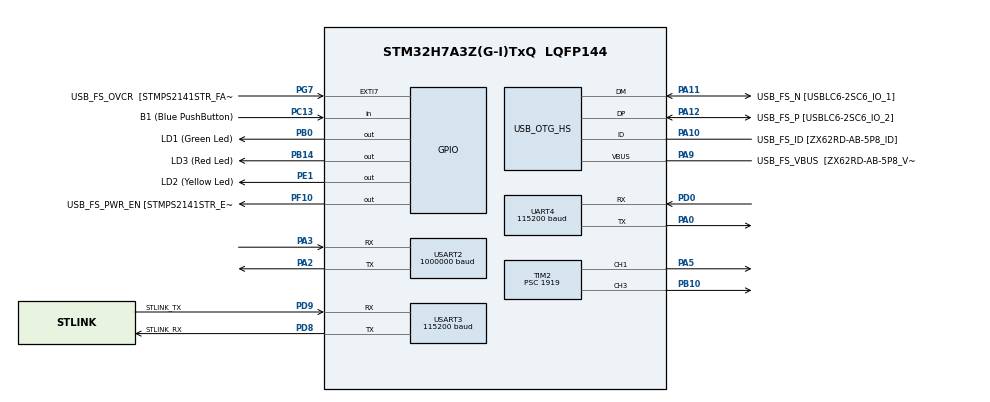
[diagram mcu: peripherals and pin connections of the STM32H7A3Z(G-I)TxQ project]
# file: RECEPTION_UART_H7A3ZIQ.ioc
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Dma.Request0=USART2_RX
Dma.USART2_RX.0.Direction=DMA_PERIPH_TO_MEMORY
Dma.USART2_RX.0.EventEnable=DISABLE
Dma.USART2_RX.0.FIFOMode=DMA_FIFOMODE_DISABLE
Dma.USART2_RX.0.Instance=DMA1_Stream0
Dma.USART2_RX.0.MemDataAlignment=DMA_MDATAALIGN_BYTE
Dma.USART2_RX.0.MemInc=DMA_MINC_ENABLE
Dma.USART2_RX.0.Mode=DMA_NORMAL
Dma.USART2_RX.0.PeriphDataAlignment=DMA_PDATAALIGN_BYTE
Dma.USART2_RX.0.PeriphInc=DMA_PINC_DISABLE
Dma.USART2_RX.0.Polarity=HAL_DMAMUX_REQ_GEN_RISING
Dma.USART2_RX.0.Priority=DMA_PRIORITY_LOW
Dma.USART2_RX.0.RequestNumber=1
Dma.USART2_RX.0.SignalID=NONE
Dma.USART2_RX.0.SyncEnable=DISABLE
Dma.USART2_RX.0.SyncPolarity=HAL_DMAMUX_SYNC_NO_EVENT
Dma.USART2_RX.0.SyncRequestNumber=1
Dma.USART2_RX.0.SyncSignalID=NONE
Mcu.Family=STM32H7
Mcu.Name=STM32H7A3Z(G-I)TxQ
Mcu.Package=LQFP144
NVIC.DMA1_Stream0_IRQn=true\:0\:0\:false\:false\:true\:false\:true\:true
NVIC.PriorityGroup=NVIC_PRIORITYGROUP_4
NVIC.TIM3_IRQn=true\:0\:0\:false\:false\:true\:true\:true\:true
NVIC.UART4_IRQn=true\:0\:0\:false\:false\:true\:true\:true\:true
PA0.Mode=Asynchronous
PA0.Signal=UART4_TX
PA10.GPIO_Label=USB_FS_ID [ZX62RD-AB-5P8_ID]
PA10.Mode=OTG/Dual-Role-Device-FS
PA10.Signal=USB_OTG_HS_ID
PA11.GPIO_Label=USB_FS_N [USBLC6-2SC6_IO_1]
PA11.Mode=OTG/Dual-Role-Device-FS
PA11.Signal=USB_OTG_HS_DM
PA12.GPIO_Label=USB_FS_P [USBLC6-2SC6_IO_2]
PA12.Mode=OTG/Dual-Role-Device-FS
PA12.Signal=USB_OTG_HS_DP
PA2.GPIO_PuPd=GPIO_PULLUP
PA2.Mode=Asynchronous
PA2.Signal=USART2_TX
PA3.Mode=Asynchronous
PA3.Signal=USART2_RX
PA5.Signal=S_TIM2_CH1_ETR
PA9.GPIO_Label=USB_FS_VBUS  [ZX62RD-AB-5P8_VBUS]
PA9.Mode=Activate_VBUS_FS
PA9.Signal=USB_OTG_HS_VBUS
PB0.GPIO_Label=LD1 (Green Led)
PB0.Signal=GPIO_Output
PB10.Signal=S_TIM2_CH3
PB14.GPIO_Label=LD3 (Red Led)
PB14.Signal=GPIO_Output
PC13.GPIO_Label=B1 (Blue PushButton)
PC13.Signal=GPIO_Input
PC14-OSC32_IN.GPIO_Label=OSC32_IN
PC14-OSC32_IN.Mode=LSE-External-Oscillator
PC14-OSC32_IN.Signal=RCC_OSC32_IN
PC15-OSC32_OUT.GPIO_Label=OSC32_OUT
PC15-OSC32_OUT.Mode=LSE-External-Oscillator
PC15-OSC32_OUT.Signal=RCC_OSC32_OUT
PD0.Mode=Asynchronous
PD0.Signal=UART4_RX
PD8.GPIO_Label=STLINK_RX
PD8.Mode=Asynchronous
PD8.Signal=USART3_TX
PD9.GPIO_Label=STLINK_TX
PD9.Mode=Asynchronous
PD9.Signal=USART3_RX
PE1.GPIO_Label=LD2 (Yellow Led)
PE1.Signal=GPIO_Output
PF10.GPIO_Label=USB_FS_PWR_EN [STMPS2141STR_EN]
PF10.Signal=GPIO_Output
PG7.GPIO_Label=USB_FS_OVCR  [STMPS2141STR_FAULT]
PG7.Signal=GPXTI7
PH0-OSC_IN.GPIO_Label=PH0-MCU
PH0-OSC_IN.Mode=HSE-External-Clock-Source
PH0-OSC_IN.Signal=RCC_OSC_IN
PH1-OSC_OUT.GPIO_Label=PH1-MCU
PH1-OSC_OUT.Signal=RCC_OSC_OUT
ProjectManager.HeapSize=0x200
ProjectManager.StackSize=0x400
ProjectManager.TargetToolchain=STM32CubeIDE
RCC.ADCFreq_Value=16125000
RCC.APB1Freq_Value=96000000
RCC.APB2Freq_Value=96000000
RCC.APB3Freq_Value=96000000
RCC.APB4Freq_Value=96000000
RCC.CortexFreq_Value=96000000
RCC.DIVM1=1
RCC.DIVM3=1
RCC.DIVN1=24
RCC.DIVN3=24
RCC.DIVQ1=4
RCC.HCLKFreq_Value=96000000
RCC.HSE_VALUE=8000000
RCC.PLLFRACN=0
RCC.PLLSourceVirtual=RCC_PLLSOURCE_HSE
RCC.PWR_Regulator_Voltage_Scale=PWR_REGULATOR_VOLTAGE_SCALE0
RCC.SYSCLKFreq_VALUE=96000000
RCC.SYSCLKSource=RCC_SYSCLKSOURCE_PLLCLK
RCC.SupplySource=PWR_DIRECT_SMPS_SUPPLY
RCC.USBCLockSelection=RCC_USBCLKSOURCE_HSI48
RCC.USBFreq_Value=48000000
SH.S_TIM2_CH1_ETR.0=TIM2_CH1,PWM Generation1 CH1
SH.S_TIM2_CH3.0=TIM2_CH3,PWM Generation3 CH3
TIM2.Channel-PWM\ Generation1\ CH1=TIM_CHANNEL_1
TIM2.Channel-PWM\ Generation3\ CH3=TIM_CHANNEL_3
TIM2.OCPolarity_3=TIM_OCPOLARITY_HIGH
TIM2.Period=999
TIM2.Prescaler=1919
TIM2.Pulse-PWM\ Generation1\ CH1=0
TIM3.ClockDivision=TIM_CLOCKDIVISION_DIV2
TIM3.Period=39999
TIM3.Prescaler=9599
UART4.BaudRate=115200
USART2.BaudRate=1000000
USART2.TxPinLevelInvertParam=ADVFEATURE_TXINV_DISABLE
USART2.VirtualMode-Asynchronous=VM_ASYNC
USART3.BaudRate=115200
USART3.VirtualMode-Asynchronous=VM_ASYNC
VP_TIM2_VS_ClockSourceINT.Mode=Internal
VP_TIM3_VS_ClockSourceINT.Mode=Internal
board=NUCLEO-H7A3ZI-Q

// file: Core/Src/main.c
/* USER CODE BEGIN Header */
/**
 ******************************************************************************
 * @file           : main.c
 * @brief          : Main program body
 ******************************************************************************
 * @attention
 *
 * Copyright (c) 2023 STMicroelectronics.
 * All rights reserved.
 *
 * This software is licensed under terms that can be found in the LICENSE file
 * in the root directory of this software component.
 * If no LICENSE file comes with this software, it is provided AS-IS.
 *
 ******************************************************************************
 */
/* USER CODE END Header */
#include "main.h"
#include "dma.h"
#include "tim.h"
#include "usart.h"
#include "usb_otg.h"
#include "gpio.h"

/* USER CODE BEGIN Includes */
#include "RPICom.h"
#include "dynamixel_protocol2.h"
#include "dynamixel_xl320.h"

/* USER CODE END Includes */

void SystemClock_Config(void);

int main(void)
{

  /* MCU Configuration--------------------------------------------------------*/

  /* Reset of all peripherals, Initializes the Flash interface and the Systick. */
  HAL_Init();

  /* Configure the system clock */
  SystemClock_Config();

  /* Initialize all configured peripherals */
  MX_GPIO_Init();
  MX_DMA_Init();
  MX_USB_OTG_HS_USB_Init();
  MX_UART4_Init();
  MX_TIM2_Init();
  MX_TIM3_Init();
  MX_USART3_UART_Init();
  MX_USART2_UART_Init();
  /* USER CODE BEGIN 2 */
  	HAL_TIM_Base_Start_IT(&htim3);
	HAL_UART_Transmit(&huart3, (uint8_t *)"\nStarting...\r\n", 14, 10);
	Process_Init();
	RPICom_Init(&huart4, &huart3);
	HAL_UART_Transmit(&huart3, (uint8_t *)"Init Done\r\n", 11, 10);

  /* USER CODE END 2 */

  /* Infinite loop */
	while (1)
	{

	}
}

void SystemClock_Config(void)
{
  RCC_OscInitTypeDef RCC_OscInitStruct = {0};
  RCC_ClkInitTypeDef RCC_ClkInitStruct = {0};

  /*AXI clock gating */
  RCC->CKGAENR = 0xFFFFFFFF;

  /** Supply configuration update enable
  */
  HAL_PWREx_ConfigSupply(PWR_DIRECT_SMPS_SUPPLY);

  /** Configure the main internal regulator output voltage
  */
  __HAL_PWR_VOLTAGESCALING_CONFIG(PWR_REGULATOR_VOLTAGE_SCALE0);

  while(!__HAL_PWR_GET_FLAG(PWR_FLAG_VOSRDY)) {}

  /** Initializes the RCC Oscillators according to the specified parameters
  * in the RCC_OscInitTypeDef structure.
  */
  RCC_OscInitStruct.OscillatorType = RCC_OSCILLATORTYPE_HSI48|RCC_OSCILLATORTYPE_HSE;
  RCC_OscInitStruct.HSEState = RCC_HSE_BYPASS;
  RCC_OscInitStruct.HSI48State = RCC_HSI48_ON;
  RCC_OscInitStruct.PLL.PLLState = RCC_PLL_ON;
  RCC_OscInitStruct.PLL.PLLSource = RCC_PLLSOURCE_HSE;
  RCC_OscInitStruct.PLL.PLLM = 1;
  RCC_OscInitStruct.PLL.PLLN = 24;
  RCC_OscInitStruct.PLL.PLLP = 2;
  RCC_OscInitStruct.PLL.PLLQ = 4;
  RCC_OscInitStruct.PLL.PLLR = 2;
  RCC_OscInitStruct.PLL.PLLRGE = RCC_PLL1VCIRANGE_3;
  RCC_OscInitStruct.PLL.PLLVCOSEL = RCC_PLL1VCOWIDE;
  RCC_OscInitStruct.PLL.PLLFRACN = 0;
  if (HAL_RCC_OscConfig(&RCC_OscInitStruct) != HAL_OK)
  {
    Error_Handler();
  }

  /** Initializes the CPU, AHB and APB buses clocks
  */
  RCC_ClkInitStruct.ClockType = RCC_CLOCKTYPE_HCLK|RCC_CLOCKTYPE_SYSCLK
                              |RCC_CLOCKTYPE_PCLK1|RCC_CLOCKTYPE_PCLK2
                              |RCC_CLOCKTYPE_D3PCLK1|RCC_CLOCKTYPE_D1PCLK1;
  RCC_ClkInitStruct.SYSCLKSource = RCC_SYSCLKSOURCE_PLLCLK;
  RCC_ClkInitStruct.SYSCLKDivider = RCC_SYSCLK_DIV1;
  RCC_ClkInitStruct.AHBCLKDivider = RCC_HCLK_DIV1;
  RCC_ClkInitStruct.APB3CLKDivider = RCC_APB3_DIV1;
  RCC_ClkInitStruct.APB1CLKDivider = RCC_APB1_DIV1;
  RCC_ClkInitStruct.APB2CLKDivider = RCC_APB2_DIV1;
  RCC_ClkInitStruct.APB4CLKDivider = RCC_APB4_DIV1;

  if (HAL_RCC_ClockConfig(&RCC_ClkInitStruct, FLASH_LATENCY_2) != HAL_OK)
  {
    Error_Handler();
  }
}

void Error_Handler(void)
{
	__disable_irq();
	while (1)
	{
	}
}
